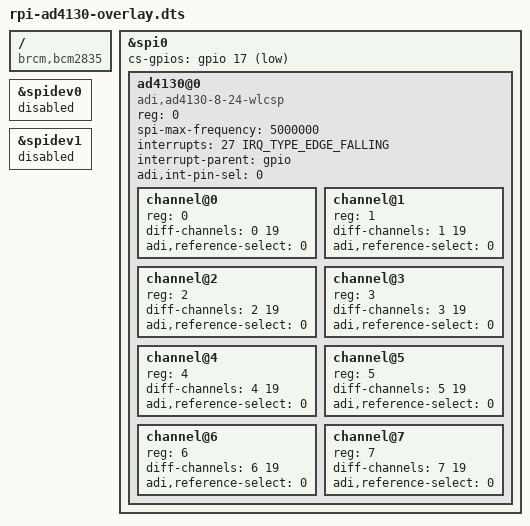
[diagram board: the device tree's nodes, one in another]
/dts-v1/;
/plugin/;

#include <dt-bindings/gpio/gpio.h>
#include <dt-bindings/interrupt-controller/irq.h>

/ {
	compatible = "brcm,bcm2835", "brcm,bcm2708", "brcm,bcm2709", "brcm,bcm2711";

	fragment@0 {
		target = <&spi0>;

		__overlay__ {
			#address-cells = <1>;
			#size-cells = <0>;

			cs-gpios = <&gpio 17 GPIO_ACTIVE_LOW>;
			status = "okay";

			ad4130@0 {
				compatible = "adi,ad4130-8-24-wlcsp";
				reg = <0>;

				#address-cells = <1>;
				#size-cells = <0>;

				spi-max-frequency = <5000000>;
				interrupts = <27 IRQ_TYPE_EDGE_FALLING>;
				interrupt-parent = <&gpio>;

				adi,int-pin-sel = <0>;

				channel@0 {
					reg = <0>;
					diff-channels = <0 19>;
					adi,reference-select = <0>;
				};

				channel@1 {
					reg = <1>;
					diff-channels = <1 19>;
					adi,reference-select = <0>;
				};

				channel@2 {
					reg = <2>;
					diff-channels = <2 19>;
					adi,reference-select = <0>;
				};

				channel@3 {
					reg = <3>;
					diff-channels = <3 19>;
					adi,reference-select = <0>;
				};

				channel@4 {
					reg = <4>;
					diff-channels = <4 19>;
					adi,reference-select = <0>;
				};

				channel@5 {
					reg = <5>;
					diff-channels = <5 19>;
					adi,reference-select = <0>;
				};

				channel@6 {
					reg = <6>;
					diff-channels = <6 19>;
					adi,reference-select = <0>;
				};

				channel@7 {
					reg = <7>;
					diff-channels = <7 19>;
					adi,reference-select = <0>;
				};
			};
		};
	};

	fragment@1 {
		target = <&spidev0>;
		__overlay__ {
			status = "disabled";
		};
	};

	fragment@2 {
		target = <&spidev1>;
		__overlay__ {
			status = "disabled";
		};
	};
};
